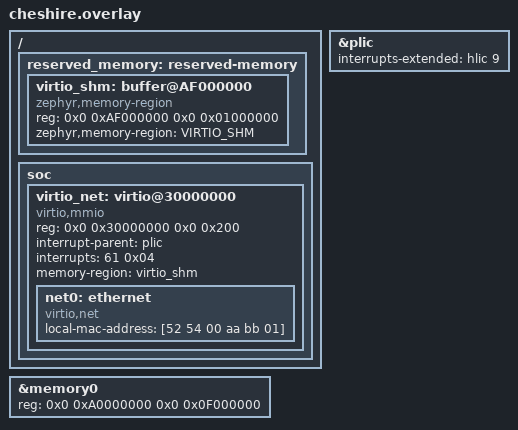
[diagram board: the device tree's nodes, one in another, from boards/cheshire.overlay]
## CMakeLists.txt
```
# SPDX-License-Identifier: Apache-2.0

cmake_minimum_required(VERSION 3.20.0)

find_package(Zephyr)
project(birtio)

zephyr_include_directories(src)
target_sources(app PRIVATE src/main.c src/virtio_shm_alloc.c)
```

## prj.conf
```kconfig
# Networking
CONFIG_NETWORKING=y
CONFIG_NET_IPV4=y
CONFIG_NET_L2_ETHERNET=y
CONFIG_NET_ARP=y
CONFIG_NET_SOCKETS=y
CONFIG_NET_TCP=y

# Console and shell
CONFIG_SERIAL=y
CONFIG_CONSOLE=y
CONFIG_UART_CONSOLE=y
CONFIG_SHELL=y
CONFIG_NET_SHELL=y
CONFIG_THREAD_MONITOR=y

# VirtIO
CONFIG_VIRTIO=y
CONFIG_VIRTIO_MMIO=y
CONFIG_ETH_VIRTIO_NET=y
CONFIG_SLIP=n
CONFIG_ETH_LOWRISC=n

# IP
CONFIG_NET_CONFIG_SETTINGS=y
CONFIG_NET_CONFIG_MY_IPV4_ADDR="192.168.1.13"
CONFIG_NET_CONFIG_MY_IPV4_NETMASK="255.255.255.0"
CONFIG_NET_CONFIG_PEER_IPV4_ADDR="192.168.1.1"

# Entropy
CONFIG_ENTROPY_GENERATOR=y
CONFIG_TEST_RANDOM_GENERATOR=y

# Buffers
CONFIG_NET_PKT_RX_COUNT=32
CONFIG_NET_PKT_TX_COUNT=16
CONFIG_NET_BUF_RX_COUNT=64
CONFIG_NET_BUF_TX_COUNT=32
CONFIG_HEAP_MEM_POOL_SIZE=32768

# Latency optimizations
CONFIG_SYS_CLOCK_TICKS_PER_SEC=1000
CONFIG_NET_RX_STACK_SIZE=2048
CONFIG_NET_SOCKETS_POLL_MAX=8

# Default settings for M-Mode
# CONFIG_RISCV_MACHINE_TIMER=y
# CONFIG_RISCV_SUPERVISOR_TIMER=n

# Supervisor mode (comment the configs below to enable S-Mode)
CONFIG_RISCV_SBI_BOOT=y
CONFIG_RISCV_S_MODE=y
CONFIG_RISCV_SUPERVISOR_TIMER=y
CONFIG_RISCV_MACHINE_TIMER=n

# enable the virtio shared memory allocator
CONFIG_VIRTIO_SHM_ALLOC=y
```

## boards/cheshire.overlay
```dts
/*
 * SPDX-License-Identifier: Apache-2.0
 * Overlay: virtio shared memory for Bao hypervisor
 */

/ {
	reserved_memory: reserved-memory {
		#address-cells = <2>;
		#size-cells = <2>;
		ranges;

		virtio_shm: buffer@AF000000 {
			compatible = "zephyr,memory-region";
			reg = <0x0 0xAF000000 0x0 0x01000000>;
			zephyr,memory-region = "VIRTIO_SHM";
		};
	};

	soc {
		virtio_net: virtio@30000000 {
			compatible = "virtio,mmio";
			reg = <0x0 0x30000000 0x0 0x200>;
			interrupt-parent = <&plic>;
			interrupts = <61 0x04>;
			status = "okay";
			memory-region = <&virtio_shm>;

			net0: ethernet {
				compatible = "virtio,net";
				status = "okay";
				local-mac-address = [52 54 00 aa bb 01];
			};
		};
	};
};

&plic {
    interrupts-extended = <&hlic 9>;
};

&memory0 {
    reg = <0x0 0xA0000000 0x0 0x0F000000>;
};
```

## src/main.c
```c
#include <zephyr/kernel.h>
#include <zephyr/devicetree.h>
#include <zephyr/net/net_if.h>
#ifdef CONFIG_VIRTIO_SHM_ALLOC
#include "virtio_shm_alloc.h"

/* Shared memory region from DTS overlay */
#define SHM_NODE  DT_NODELABEL(virtio_shm)
#define SHM_ADDR  DT_REG_ADDR(SHM_NODE)
#define SHM_SIZE  DT_REG_SIZE(SHM_NODE)

/* Init shared memory allocator before drivers (PRE_KERNEL_1).
 * The virtio_mmio driver inits at POST_KERNEL, so this runs first.
 */
static int virtio_shm_sys_init(void)
{
	virtio_shm_init(SHM_ADDR, SHM_SIZE);
	return 0;
}

SYS_INIT(virtio_shm_sys_init, PRE_KERNEL_1, 0);
#endif

int main(void)
{
	printk("*** Virtio-net shared memory demo ***\n");
	printk("SHM base: 0x%lx, size: 0x%lx\n",
	       (unsigned long)SHM_ADDR, (unsigned long)SHM_SIZE);

	/* Wait for the network interface to come up */
	struct net_if *iface = net_if_get_default();

	if (!iface) {
		printk("No network interface found\n");
		return -1;
	}

	printk("Network interface ready, use shell: net ping <ip>\n");

	return 0;
}


// #include <zephyr/kernel.h>
// #include <zephyr/net/net_if.h>
// #include <zephyr/net/net_core.h>
// #include <zephyr/net/icmp.h>
// #include <zephyr/net/net_ip.h>

// static struct net_icmp_ctx icmp_ctx;
// static struct k_sem ping_sem;
// static bool ping_received;

// static int ping_handler(struct net_icmp_ctx *ctx,
//                         struct net_pkt *pkt,
//                         struct net_icmp_ip_hdr *hdr,
//                         struct net_icmp_hdr *icmp_hdr,
//                         void *user_data)
// {
//     ping_received = true;
//     k_sem_give(&ping_sem);
//     return 0;
// }

// int main(void)
// {
//     struct net_if *iface;
//     struct sockaddr_in dst;
//     int ret;

//     printk("\n=== LowRISC Ethernet Ping Test ===\n");

//     k_sleep(K_SECONDS(3));

//     iface = net_if_get_default();
//     if (iface == NULL) {
//         printk("ERROR: No interface\n");
//         return 0;
//     }

//     struct net_linkaddr *ll = net_if_get_link_addr(iface);
//     printk("MAC: %02x:%02x:%02x:%02x:%02x:%02x\n",
//            ll->addr[0], ll->addr[1], ll->addr[2],
//            ll->addr[3], ll->addr[4], ll->addr[5]);
//     printk("Link: %s\n", net_if_is_carrier_ok(iface) ? "UP" : "DOWN");

//     k_sem_init(&ping_sem, 0, 1);

//     /* Register ICMP echo reply handler */
//     ret = net_icmp_init_ctx(&icmp_ctx, AF_INET, NET_ICMPV4_ECHO_REPLY, 0, ping_handler);
//     if (ret < 0) {
//         printk("ERROR: ICMP init failed: %d\n", ret);
//         return 0;
//     }

//     /* Target: your PC */
//     memset(&dst, 0, sizeof(dst));
//     dst.sin_family = AF_INET;
//     net_addr_pton(AF_INET, "192.168.1.100",
//                   &dst.sin_addr);

//     printk("Pinging 192.168.1.100 ...\n\n");

//     for (int i = 0; i < 5; i++) {
//         ping_received = false;

//         struct net_icmp_ping_params params = {
//             .identifier = 0x1234,
//             .sequence = i,
//             .tc_tos = 0,
//         };

//         int64_t start = k_uptime_get();

//         ret = net_icmp_send_echo_request(&icmp_ctx, iface,
//                                          (struct sockaddr *)&dst,
//                                          &params, NULL);
//         if (ret < 0) {
//             printk("Ping %d: send failed (%d)\n", i, ret);
//         } else {
//             /* Wait up to 3 seconds for reply */
//             ret = k_sem_take(&ping_sem, K_SECONDS(3));
//             if (ret == 0 && ping_received) {
//                 int64_t elapsed = k_uptime_get() - start;
//                 printk("Ping %d: reply in %lld ms\n", i, elapsed);
//             } else {
//                 printk("Ping %d: timeout\n", i);
//             }
//         }

//         k_sleep(K_SECONDS(1));
//     }

//     net_icmp_cleanup_ctx(&icmp_ctx);
//     printk("\n=== Ping test complete ===\n");
//     return 0;
// }
```

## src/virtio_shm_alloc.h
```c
#ifndef VIRTIO_SHM_ALLOC_H
#define VIRTIO_SHM_ALLOC_H

#include <stddef.h>
#include <stdint.h>

/**
 * Inicializa el allocator sobre la región de memoria compartida.
 * Se llama una vez al arranque, antes de que se inicialice el driver virtio.
 */
void virtio_shm_init(uintptr_t base, size_t size);

/**
 * Asigna 'size' bytes alineados a 'align' dentro de la región compartida.
 * Retorna NULL si no hay espacio.
 */
void *virtio_shm_alloc(size_t size, size_t align);

/**
 * No-op. El bump allocator no soporta free individual.
 */
void virtio_shm_free(void *ptr);

#endif
```
